# pse84 register map
Vendor: Infineon Technologies; Series: PSE84; File version: 1.0
CPU: CM33 r0p1, little endian, MPU, FPU, VTOR, 3 interrupt priority bits
Registers are 32-bit, read-write, reset 0x0 unless marked. A register's access mark holds for its fields unless they carry their own. Offsets are from the block's base; [hi:lo] are bit positions; lines under a group give offsets from that group; {n}, {i} and the like mark numbered series; <NAME> marks a mode.

## RRAMC0 — RRAM controller registers
Base 0x42200000
0x10000 RRAMC group — RRAMC controller registers
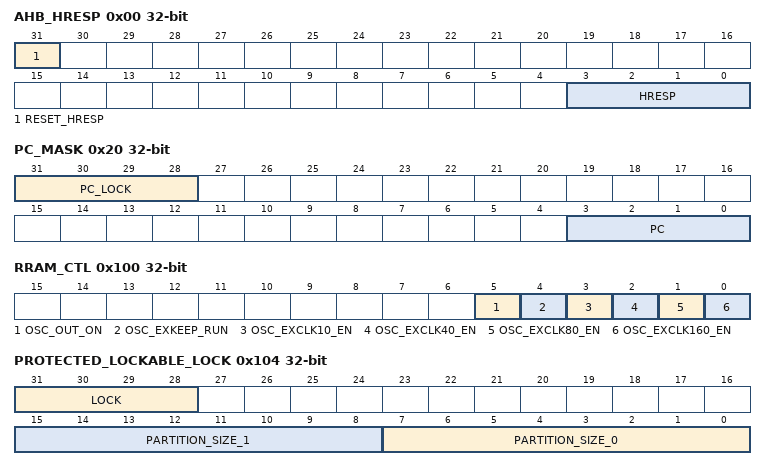
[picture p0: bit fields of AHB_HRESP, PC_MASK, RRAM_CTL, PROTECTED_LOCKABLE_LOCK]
  0x00 AHB_HRESP — RRAMC AHB HRESP
    [31] RESET_HRESP — 0: No reset to AHB_HRESP 1: Triggering reset to AHB_HRESP by hardware after one clock cycle
    [3:0] HRESP ro — 4'b0000: No AHB bus error 4'b0001: OTP Tagbit[2:0] violation during write (the target OTP is tagged 3'b111) or wrong interface updating OTP. 4'b0010: Post-read check Tagbit[2:0] violation during read (when target NVM/OTP tagged other than 3'b000) 4'b0011: Post-read check address fault alarm 4'b0100: RARM IP AHB bus error (Needs to read RRAM SFR NVM_HRESP for causes of the error) 4'b0101: Incomplete write or 8/16 write on the protected interface 4'b0110: Indirect sequence where AHB write address mismatch with SFR NVM_ADDR on the protected interface or direct write target address not in defined range on the BISR interface 4'b0111: Programming PROTECTED_NVM lockable subsection when PROTECTED_LOCKABLE_LOCK.LOCK is locked (write-protected) 4'b1000: 4'b1001: Detecting UDS read access while UDS is locked 4'b1010: 4'b1011: 4'b1100: Executing indirect operation without a PC acquired 4'b1101: Transaction PC is different (or same PC but different HMASTER_ID) than the acquired PC or transaction PC is not PC0 in VIRGIN/SORT LCS 4'b1110: Executing forming or looped forming in SORT LCS 4'b1111: Protected interface MPC violation
  0x20 PC_MASK — PC acquisition and releasing
    [31:28] PC_LOCK — 4'b0000: Not locked, any PC can lock again 4'b1111: PC [3:0] locked PC_LOCK is redundantly implemented. Any other bit encoding during programming or at any instance in time, AHB bus error (while programming) is generated and fault/interrupt is triggered to the system fault reporting infrastructure
    [3:0] PC ro — PC allowed for an indirect sequence
  0x24 RRAM_PROTECTED_X ro — Size of PROTECTED_NVM subregion (8KB * X)
    [31:0] PROTECTED_X — Size of PROTECTED_NVM, same value as RTL parameter PROTECTED_X
  0x28 RRAM_SFLASH_Y ro — Size of SFLASH_NVM subregion (8KB * Y)
    [31:0] SFLASH_Y — Size of SFLASH_NVM, same value as RTL parameter SFLASH_Y
  0x2C RRAM_WORK_Z ro — Size of WORK_NVM subregion (8KB * Z)
    [31:0] WORK_Z — Size of WORK_NVM, same value as RTL parameter WORK_Z
  0x30 RRAM_MAIN_N ro — Size of MAIN_NVM subregion (8KB * N)
    [31:0] MAIN_N — Size of MAIN_NVM, same value as RTL parameter MAIN_N
  0x100 RRAM_CTL — RRAM macro OSC control
    [5] OSC_OUT_ON — Enables the RRAM macro oscillator output after RRAM reset. Determines the reset value of NVM_OSCCONF.OSC_OUT Static signal of RRAM macro. 0: Disabled . 1: Enabled.
    [4] OSC_EXKEEP_RUN — Keep internal oscillator running. If osc_exkeeprun_i is '0', and the FSM signals the internal oscillator to switch off, it is really switched off (without generating spikeson the clock signal). If osc_exkeeprun_i is '1' and the FSM signals the internal oscillator to switch off, it is not switched off. Instead it waits for osc_exkeeprun_i to become '0' and then isswitched off (without generating spikes on the clock signal). When osc_exkeeprun_i becomes'1', the internal oscillator is switched on again. Note: For NVM_OSCCONF.OSC_ON = '0', the oscillator is switched off independent of signal osc_exkeeprun_i.
    [3] OSC_EXCLK10_EN — Enables the RRAM macro oscillator output with oscillator frequency/16. 0: Disabled . 1: Enabled. This is effective only when OSC_OUT_ON is 1.
    [2] OSC_EXCLK40_EN — Enables the RRAM macro oscillator output with oscillator frequency/4. 0: Disabled . 1: Enabled. This is effective only when OSC_OUT_ON is 1.
    [1] OSC_EXCLK80_EN — Enables the RRAM macro oscillator output with oscillator frequency/2. 0: Disabled . 1: Enabled. This is effective only when OSC_OUT_ON is 1.
    [0] OSC_EXCLK160_EN — Enables the RRAM macro oscillator output with default oscillator frequency. 0: Disabled . 1: Enabled. This is effective only when OSC_OUT_ON is 1.
  0x104 PROTECTED_LOCKABLE_LOCK — PROTECTED_NVM lockable configuarion
    [31:28] LOCK — 4'b0000: Not locked, PARTITION_SIZE_0/1 changes and lockable programming are allowed 4'b1111: Locked, PARTITION_SIZE_0/1 changes and Lockable programming are NOT allowed except the topmost 1KB of lockable which is always writable regardless of 'LOCK' status The MXS22RRMC logic allows only 4'b0000 and 4'b1111. Any other bit encoding during programming or at any instance in time, AHB bus error (while programming) is generated and fault/interrupt is triggered to the host (fault reporting infrastructure) Trying to program PROTECTED_NVM lockable subsection or program/change PARTITION_SIZE_0/1 during locked LOCK triggers AHB bus error SW can write to PARTITION_SIZE and LOCK at the same transaction
    [15:8] PARTITION_SIZE_1 — Redundant implementation of the size encoding If bit[7:0] and bit[15:8] are different during programming or at any instance in time, AHB bus error (while programming) is generated and fault/interrupt is triggered to the system fault reporting infrastructure SW must write both PARTITION_SIZE_0/1 at the same transaction
    [7:0] PARTITION_SIZE_0 — 8'h00: 1KB lockable subsection in PROTECTED_NVM 8'h01: 2KB lockable subsection in PROTECTED_NVM 8'h02: 3KB lockable subsection in PROTECTED_NVM .. .. 8'hfd: 254KB lockable subsection in PROTECTED_NVM 8'hfe: 255KB lockable subsection in PROTECTED_NVM 8'hff: 256KB lockable subsection in PROTECTED_NVM In case size is larger than PROTECTERD_NVM, the entire PROTECTED_NVM is lockable, there is no upgradable subsection
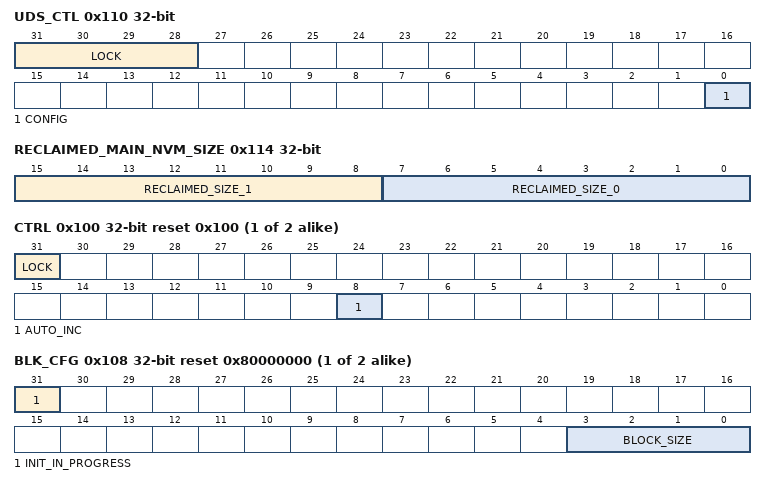
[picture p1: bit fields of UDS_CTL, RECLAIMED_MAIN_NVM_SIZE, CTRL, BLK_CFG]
  0x110 UDS_CTL — UDS control
    [31:28] LOCK — 4'b0000: Not locked 4'b1111: Locked. No access to UDS_KEY. Once locked, cannot be changed till next reset The MXS22RRMC logic allows only 4'b0000 and 4'b1111. Any other bit encoding during programming or at any instance in time, AHB bus error (while programming) is generated and fault/interrupt is triggered to the system fault reporting infrastructure
    [0] CONFIG — 1'b0: When LOCKED, read access triggers 'read-as-zero' and no error 1'b1: When LOCKED, read access triggers AHB bus error
  0x114 RECLAIMED_MAIN_NVM_SIZE — Reclaimed size (KB) from upgradeable
    [15:8] RECLAIMED_SIZE_1 — Redundant implementation of RECLAIMED_SIZE encoding If bit[7:0] and bit[15:8] are different during programming or at any instance in time, AHB bus error (while programming) is generated and fault/interrupt is triggered to the system fault reporting infrastructure SW must write both RECLAIMED_SIZE_0/RECLAIMED_SIZE_1 at the same transaction
    [7:0] RECLAIMED_SIZE_0 — 8'h00: 0KB upgradeable reclaimed from PROTECTED_NVM 8'h01: 1KB upgradeable reclaimed from PROTECTED_NVM 8'h02: 2KB upgradeable reclaimed from PROTECTED_NVM .. .. 8'hfd: 253KB upgradeable reclaimed from PROTECTED_NVM 8'hfe: 254KB upgradeable reclaimed from PROTECTED_NVM 8'hff: 255KB upgradeable reclaimed from PROTECTED_NVM In case the size of the reclaimed is larger than PROTECTERD_NVM, the entire PROTECTED_NVM is reclaimed, there is no PROTECTED_NVM
  0x118 TB_GATING_CTL reset 0xF0000000 — Turn-off Tagbit post-read gating control check
    [31:28] TB_GATING_OFF — 4'b0000: Gating control on 4'b1111: Gating control off (in test mode) The MXS22RRMC logic allows only 4'b0000 and 4'b1111. Any other bit encoding during programming or at any instance in time, AHB bus error (while programming) is generated and fault/interrupt is triggered to the system fault reporting infrastructure Write 4'b1111 (once only) to clear to 4'b0000, write 4'b0000 is ignored (no error response/no fault)
{0x11000+0x1000*i} MPC[{i}] (i=0..1) group — MPC Memory Protection Controller registers
  0x00 CFG — Config register with error response, RegionID PPC_MPC_MAIN is the security owner PC. The error response configuration is located in CFG.RESPONSE, only one such configuration exists applying to all protection contexts in the system.
    [4] RESPONSE — Response Configuration for Security and PC violations 0: Read-Zero Write Ignore (RAZ/WI) 1: Bus Error
  0x100 CTRL reset 0x100 — Control register with lock bit and auto-increment only (Separate CTRL for each PC depends on access_pc)
    [31] LOCK — Security lockdown for this protection context. Software can set this bit but not clear it once set. When set, write operations to BLK_LUT are not possible from this protection context. Setting LOCK also blocks writes to CTRL itself (for that PC copy). All writes are ignored.
    [8] AUTO_INC — Auto-increment BLK_IDX by 1 for this protection context as a side effect of each read/write access to BLK_LUT
  0x104 BLK_MAX ro — Max value of block-based index register
    [31:0] VALUE — Maximum value of block-based index register. The number and size blocks in an MPC is design time configurable and for embedded memories defaults to covering the entire memory using 4kB blocks; See product datasheet for details on protection of external memories.
  0x108 BLK_CFG ro reset 0x80000000 — Block size & initialization in progress
    [31] INIT_IN_PROGRESS — During initialization INIT_IN_PROGRESS is '1' and MMIO register accesses to BLK_LUT is blocked (BLK_IDX increment is also ignored). The block attributes are retained in DeepSleep (and obviously Active) power mode. Initialization is only required from a power mode in which the block attributes are not retained. E.g., initialization is required for a cold boot (after a Power-on-Reset). HW initializes the block attributes: the NS attributes are set to '0' (secure), the R attributes are set to '1' (read access allowed) and the W attributes are set to '1' (write access allowed). During initialization, the MPC supports memory accesses (memory accesses are NOT blocked) with the initialization block attribute values as mentioned above. This e.g. allows MPC initialization to proceed in parallel with boot program memory accesses (as opposed to serializing the two), improving device boot time.
    [3:0] BLOCK_SIZE — Block size of individually protected blocks (0: 32B, 1: 64B, ... up to 15: 1MB) Block size= (1<<(BLOCK_SIZE+5)) The number and size blocks in an MPC is design time configurable and for embedded memories defaults to covering the entire memory using 4kB blocks; see product datasheet for details on protection of external memories.
  0x10C BLK_IDX — Index of 32-block group accessed through BLK_LUT (Separate IDX for each PC depending on access_pc)
    [31:0] VALUE — Index value for accessing block-based lookup table using BLK_LUT. Programming out of LUT range is an user error and it loops back to '0' once overflow occurs.
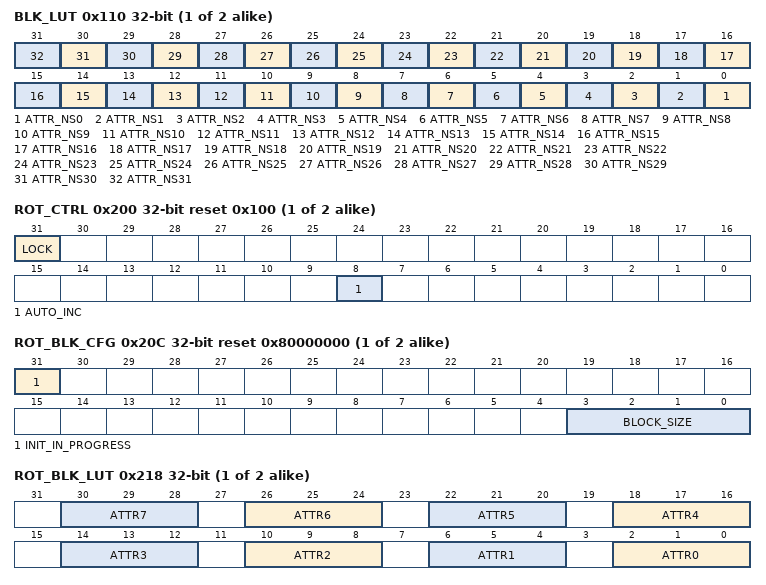
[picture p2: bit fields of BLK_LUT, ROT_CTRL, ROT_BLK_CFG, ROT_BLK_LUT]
  0x110 BLK_LUT — NS status for 32 blocks at BLK_IDX with PC=<access_pc>
    [n] ATTR_NS{n} (n=0..31) — NS bit for block {n} based on BLK_IDX
  0x200 ROT_CTRL reset 0x100 — Control register with lock bit and auto-increment only
    [31] LOCK — Security lockdown for the root-of-trust configuration registers. Software can set this bit but not clear it once set. When set, write operations to ROT_BLK_LUT are not possible. Write is ignored.
    [8] AUTO_INC — Auto-increment BLK_IDX by 1 for each read/write of ROT_BLK_LUT
  0x208 ROT_BLK_MAX ro — Max value of block-based index register for ROT
    [31:0] VALUE — Maximum value of block-based index register. The number and size blocks in an MPC is design time configurable and for embedded memories defaults to covering the entire memory using 4kB blocks; see product datasheet for details on protection of external memories.
  0x20C ROT_BLK_CFG ro reset 0x80000000 — Same as BLK_CFG
    [31] INIT_IN_PROGRESS — During initialization INIT_IN_PROGRESS is '1' and MMIO register accesses to ROT_BLK_LUT is RAZWI. The block attributes are retained in DeepSleep (and obviously Active) power mode. Initialization is only required from a power mode in which the block attributes are not retained. E.g., initialization is required for a cold boot (after a Power-on-Reset). HW initializes the block attributes: the NS attributes are set to '0' (secure), the R attributes are set to '1' (read access allowed) and the W attributes are set to '1' (write access allowed). During initialization, the MPC supports memory accesses (memory accesses are NOT blocked) with the initialization block attribute values as mentioned above. This e.g. allows MPC initialization to proceed in parallel with boot program memory accesses (as opposed to serializing the two), improving device boot time.
    [3:0] BLOCK_SIZE — Block size of individually protected blocks (0: 32B, 1: 64B, ...up to 15:1MB) Block size= (1<<(BLOCK_SIZE+5)) The number and size blocks in an MPC is design time configurable and for embedded memories defaults to covering the entire memory using 4kB blocks; see product datasheet for details on protection of external memories.
  0x210 ROT_BLK_IDX — Index of 8-block group accessed through ROT_BLK_LUT_*
    [31:0] VALUE — Index value for accessing block-based lookup table using ROT_BLK_LUT. Programming out of LUT range is an user error and it loops back to '0' once overflow occurs.
  0x214 ROT_BLK_PC — Protection context of 8-block group accesses through ROT_BLK_LUT
    [3:0] PC — Specify PC values for ROT_BLK_IDX and ROT_BLK_LUT
  0x218 ROT_BLK_LUT — (R,W,NS) bits for 8 blocks at ROT_BLK_IDX for PC=ROT_BKL_PC
    [4n+2:4n] ATTR{n} (n=0..7) — W/R/NS bits for block {n} indicated by ROT_BLK_IDX for ROT_BLK_PC PC
0x13000 RRAM_SFR group — RRAM macro SFR registers
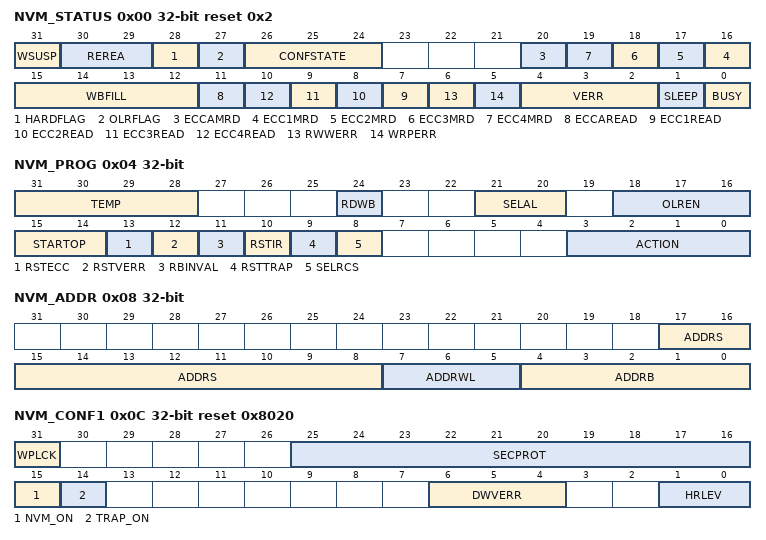
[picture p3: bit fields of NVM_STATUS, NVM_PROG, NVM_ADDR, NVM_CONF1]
  0x00 NVM_STATUS ro reset 0x2 — status register
    [31] WSUSP
    [30:29] REREA
    [28] HARDFLAG
    [27] OLRFLAG
    [26:24] CONFSTATE
    [20] ECCAMRD
    [n+15] ECC{n}MRD (n=1..4)
    [15:12] WBFILL — Filling state for the write-buffer data words. E.g. WBFILL = 0000 (Write-Buffer invalid), WBFILL = 0011 (Write-Buffer intermediate), WBFILL = 1111 (Write-Buffer valid) The bits of WBFILL are set by the hardware, when write, verify-only, or forming data is written into the write-buffer. WBFILL is reset after each direct write, online-repair, or hardening operation.
    [11] ECCAREAD
    [n+6] ECC{n}READ (n=1..4)
    [6] RWWERR
    [5] WRPERR
    [4:2] VERR
    [1] SLEEP
    [0] BUSY
  0x04 NVM_PROG — programming control register
    [31:28] TEMP — actual junction temperature: 0000: invalid/unknown junction temperature value. others: junction temperature value to be used for voltage compensation in programming algorithms. Example for coding: 0001: Tj <= 50C 0010: 50C < Tj <= 85C 0100: 85C < Tj <= 100C 1000: 100C < Tj <= 110C 1010: 110C < Tj <=120C 1100: Tj > 120C Note: The coding has to use increasing values of TEMP for increasing temperatures and it has to match to the coding employed in NVM_COMPEN.TMIN*.
    [24] RDWB — Read from write-buffer: 0: disabled. 1: enabled for memory bus reads with ACTION = ['0001', '0010', '1000', '1110', '0111'] and read address matching content of NVMADDR. RDWB is automatically reset, when the content of the write-buffer is invalidated or when ACTION is changed.
    [21:20] SELAL — Select type of write algorithm: 00: Employ first (typically standard, 8 bit parallel) algorithm defined by NVM_SELALGO1.SEL*ALGO1. 01: Employ second (typically strong, 8 bit parallel) algorithm defined by NVM_SELALGO1.SEL*ALGO2. 1x: Employ third (typically standard, 1 bit parallel) algorithm defined by NVM_SELALGO2.SEL*ALGO3.
    [18:16] OLREN — 000: disable online-repair (OLR). 001: enable online-repair for >= single-bit write or forming fail in block. 010: enable online-repair for >= double-bit write or forming fail in block. 011: enable online-repair for>= triple-bit write or forming fail in block. 1xx: enable online-repair for > triple-bit write or forming fail in block.
    [15:14] STARTOP — Can only be set by software, is reset automatically by hardware after one clock cycle. 00: No start of operation defined by ACTION. 11: Start operation defined by ACTION, if these are not changed with the same write operation that sets STARTOP. Others: Interpreted and stored in SFR as '00'.
    [13] RSTECC — Can only be set by software, is reset automatically by hardware after one clock cycle. 0: No reset of NVM_STATUS.ECC*READ, NVM_STATUS.REREA, NVM_STATUS.RWWERR, and NVM_STATUS.WRPERR. 1: Reset of NVM_STATUS.ECC*READ, NVM_STATUS.REREA, NVM_STATUS.RWWERR, and NVM_STATUS.WRPERR.
    [12] RSTVERR — Can only be set by software, is reset automatically by hardware after one clock cycle. 0: No reset of NVM_STATUS.VERR, NVM_STATUS.HARDFLAG, and NVM_STATUS.OLRFLAG. 1: Reset of NVM_STATUS.VERR, NVM_STATUS.HARDFLAG, and NVM_STATUS.OLRFLAG.
    [11] RBINVAL — Can only be set by software, is reset automatically by hardware after one clock cycle. 0: No invalidation of read-buffer content. 1: Invalidation of read-buffer content.
    [10] RSTIR — Can only be set by software, is reset automatically by hardware after one clock cycle. 0: No reset of ECC logging interrupt on nvm_ir_ecclog_req_o. 1: Reset of ECC logging interrupt on nvm_ir_ecclog_req_o.
    [9] RSTTRAP — Can only be set by software, is reset automatically by hardware after one clock cycle. 0: No reset of NVM ready trap on nvm_trap_req_o. 1: Reset of NVM ready trap on nvm_trap_req_o.
    [8] SELRCS — Select parameter for operation 'retrieve configuration settings' from configuration space in extra area. 0: Retrieve SYSCONF information and configuration settings, but do not retrieve write algorithm information. 1: Retrieve SYSCONF information, configuration settings, and write algorithm information. Note: SELRCS only applies to the sequence explicitly started with ACTION = '1011', but not to the implicitly started sequences during wake-up and write sequences
    [3:0] ACTION — Selects indirect write, verify-only, hardening or forming operations: 0000: Idle state, no action triggered. Writing '0000' exits current mode. 0001: Select indirect write operation, using algorithm selected by SELAL, NVM_SELALGO1/2.SEL*ALGO1/2/3, and NVM_SETUP1.FSMSEQ. 0010: Select verify-only: Written data is compared to array content. 0100: Select hardening: Existing data is verified and hardened/corrected if necessary. 1000: Select forming operation, using algorithm selected by NVM_SELALGO2.SELFALGO. 1110: Select looped write operation, using algorithm selected by SLSTRAL, NVM_SELALGO1/2.SEL*ALGO1/2/3, and NVM_SETUP1.FSMSEQ; cannot be set, if NVM_ACC.ACC2_EN = '0'. Note: Only to be used in production test flow. 0111: Select looped forming operation, using algorithm selected by NVM_SELALGO2.SELFALGO; cannot be set, if NVM_ACC.ACC2_EN = '0'. Note: Only to be used in production test flow. 1011: Select operation 'retrieve configuration settings' from configuration space in extra area; cannot be set, if NVM_ACC.ACC3_EN = '0'. Others: Interpreted and stored in SFR as '0000' The operation selected by ACTION is performed, when STARTOP = '11' is written while ACTION stays constant. NVM_ADDR defines the address for the operation. Verification results can be read at NVM_STATUS.VERR. ACTION can only be changed to a value other than '0000', if the current value of ACTION is '0000'. Otherwise ACTION = '0000' is stored. Once ACTION is set to a value other than '0000', ACTION can only be written again with its current value; any other value leads to a reset of ACTION to '0000'
  0x08 NVM_ADDR — address register
    [17:8] ADDRS — sector address for operations started with NVM_PROG.
    [7:5] ADDRWL — wordline address for operations started with NVM_PROG.
    [4:0] ADDRB — block address for operations started with NVM_PROG.
  0x0C NVM_CONF1 reset 0x8020 — configuration register
    [31] WPLCK — Locking of protection settings in SECPROT: 0: SECPROT can be changed. 1: SECPROT cannot be changed. WPLCK cannot be written by software, if it is '1'.
    [25:16] SECPROT — number of write protected sectors, starting with sector 0. SECPROT cannot be changed, if WPLCK = '1'.
    [15] NVM_ON — 0: NVM is switched to or stays in NVM sleep mode. 1: NVM is switched to or stays in normal mode.
    [14] TRAP_ON — 0: no NVM ready traps are generated on nvm_trap_req_o. 1: NVM ready traps are generated when long lasting NVM actions (indirect write, hardening, forming, and wake-up) are finished Note: Direct write operations and verify-only operations never generate a ready trap.
    [6:4] DWVERR — for direct write operations, defines the threshold for a verify error indication: 000: verify is pass only, if no fail bit. 001: verify is pass only, if at most a single-bit fail. 010: verify is pass only, if at most a double-bit fail. 011: verify is pass only, if at most a triple-bit fail. 1xx: verify is always pass, independent of any fail bits.
    [1:0] HRLEV — defines single hardread level for verify-only operation started for NVM_PROG.ACTION = '0010': 00: normal read. 01: hardread reset. 1x: hardread set.
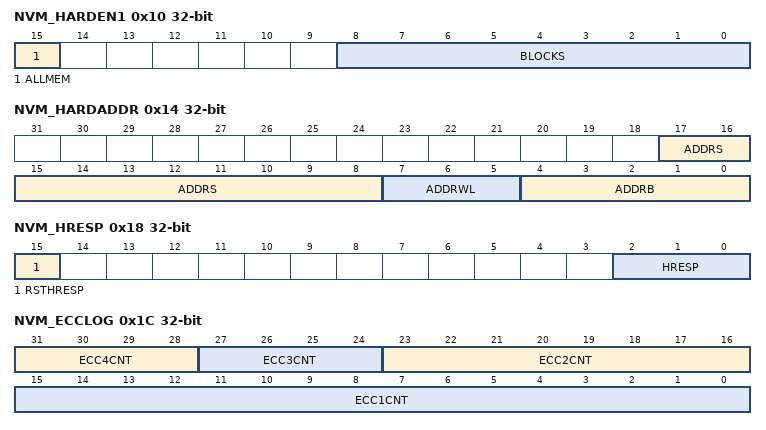
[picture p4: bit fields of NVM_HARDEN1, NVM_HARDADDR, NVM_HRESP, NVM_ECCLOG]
  0x10 NVM_HARDEN1 — hardening configuration register
    [15] ALLMEM — selected address range for hardening operation: 0: defined by NVM_ADDR and BLOCKS. 1: complete memory.
    [8:0] BLOCKS — BLOCKS+1 defines number of blocks in address range selected for hardening: start of hardening address range = NVM_ADDR end of hardening address range = NVM_ADDR + BLOCKS only valid for ALLMEM = '0'
  0x14 NVM_HARDADDR — hardening address register
    [17:8] ADDRS — sector address for automatic hardening
    [7:5] ADDRWL — wordline address for automatic hardening
    [4:0] ADDRB — block address for automatic hardening
  0x18 NVM_HRESP — bus response register
    [15] RSTHRESP — reset of NVM_HRESP: 0: no reset of HRESP triggered trigger 1: reset of HRESP RSTHRESP is reset automatically by hardware after one clock cycle
    [2:0] HRESP ro
  0x1C NVM_ECCLOG ro — ECC failure logging register
    [31:28] ECC4CNT — Number of ECC-uncorrectable multi-bit failures detected during the last memory read operations (or the initial reading of existing data for a write operation). ECC4CNT is only updated, if NVM_TEST1.ECCOFFRD = '0x' and if even the last re-read operation (configured in NVM_SETUP1.REREAD) still yields an ECC-uncorrectable multi-bit failure. For NVM_TEST1.ECCOFFRD = '1x', ECC4CNT stays unchanged.
    [27:24] ECC3CNT — Number of ECC triple-bit failures detected and corrected during the last memory read operations (or the initial reading of existing data for a write operation). ECC3CNT is only updated, if NVM_TEST1.ECCOFFRD = '0x' and if even the last re-read operation (configured in NVM_SETUP1.REREAD) yields an ECC triple-bit failure. For NVM_TEST1.ECCOFFRD = '1x', ECC3CNT stays unchanged.
    [23:16] ECC2CNT — Number of ECC double-bit failures detected and corrected during the last memory read operations (or the initial reading of existing data for a write operation). ECC2CNT is only updated, if NVM_TEST1.ECCOFFRD = '0x' and if even the last re-read operation (configured in NVM_SETUP1.REREAD) yields an ECC double-bit failure. For NVM_TEST1.ECCOFFRD = '1x', ECC2CNT stays unchanged.
    [15:0] ECC1CNT — Number of ECC single-bit failures detected and corrected during the last memory read operations (or the initial reading of existing data for a write operation). ECC1CNT is only updated, if NVM_TEST1.ECCOFFRD = '0x' and if even the last re-read operation (configured in NVM_SETUP1.REREAD) yields an ECC single-bit failure. For NVM_TEST1.ECCOFFRD = '1x', ECC1CNT stays unchanged.
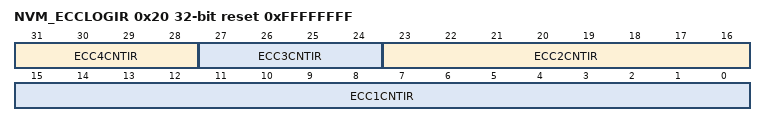
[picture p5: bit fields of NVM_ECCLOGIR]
  0x20 NVM_ECCLOGIR reset 0xFFFFFFFF — ECC failure logging interrupt register
    [31:28] ECC4CNTIR — Interrupt threshold for number of ECC-uncorrectable multi-bit failures indicated in NVM_ECCLOG.ECC4CNT: If NVM_ECCLOG.ECC4CNT becomes larger than ECC4CNTIR, an ECC logging interrupt is triggered.
    [27:24] ECC3CNTIR — Interrupt threshold for number of ECC triple-bit failures indicated in NVM_ECCLOG.ECC3CNT: If NVM_ECCLOG.ECC3CNT becomes larger than ECC3CNTIR, an ECC logging interrupt is triggered
    [23:16] ECC2CNTIR — Interrupt threshold for number of ECC double-bit failures indicated in NVM_ECCLOG.ECC2CNT: If NVM_ECCLOG.ECC2CNT becomes larger than ECC2CNTIR, an ECC logging interrupt is triggered.
    [15:0] ECC1CNTIR — Interrupt threshold for number of ECC single-bit failures indicated in NVM_ECCLOG.ECC1CNT: If NVM_ECCLOG.ECC1CNT becomes larger than ECC1CNTIR, an ECC logging interrupt is triggered.
  0x24 NVM_VMODE — voltage mode register
    [1:0] VMODE — voltage/frequency mode for operations: 00: undefined / unknown 01: ULP mode 10: MF mode 11: LP mode
